AUTOSAR XML (schema 4-3-0)
standard types defined: boolean, float32, boolean_CompuMethod, boolean_DataConstr, float32_DataConstr, sint16, sint32, uint32, uint8, sint16_DataConstr, sint32_DataConstr, uint32_DataConstr, uint8_DataConstr, uint16
package /ASP_DataTypes
  impl type As_Coord2F32: category=STRUCTURE
    element x: implementation-data-type=ASP_DataTypes/float32
    element y: implementation-data-type=ASP_DataTypes/float32
package /ComponentTypes/HkmcComponent/HkmcFcaAdap
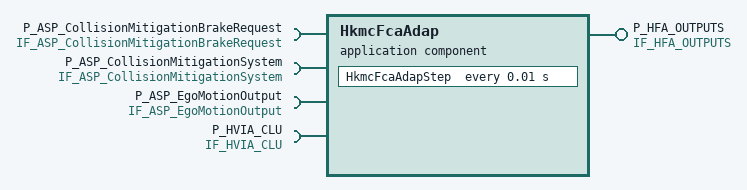
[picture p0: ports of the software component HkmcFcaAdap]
  application sw component type HkmcFcaAdap
    provide port P_HFA_OUTPUTS: nonqueued-sender-com-spec{data-element=DE_HFA_OUTPUTS, init-value=fields=[FcaAdap_WrngLvlSta:0, FcaAdap_WrngSndSta:0, FcaAdap_PrefillActvReq:0, FcaAdap_DclReqVal:0, FcaAdap_FullActvReq:0, FcaAdap_StbltActvReq:0, FcaAdap_VehStpReq:0, FcaAdap_OnOffEquipSta:0, FcaAdap_SysFlrSta:0, FcaAdap_RelVel:0, FcaAdap_TimetoCllsn:0, FcaAdap_SnstvtyModRetVal:0, FcaAdap_LongitudinalVelocity:0, FcaAdap_ObjectType:0, FcaAdap_WarningRequest:0, FcaAdap_CollisionThreatLevel:0, FcaAdap_DecelerationRequest:0, FcaAdap_StandStillRequest:0]}, provided-interface=IF_HFA_OUTPUTS
    4 x require port:
      P_ASP_CollisionMitigationBrakeRequest: nonqueued-receiver-com-spec{data-element=DE_ASP_CollisionMitigationBrakeRequest, filter=data-filter-type=ALWAYS, init-value=fields=[DecelerationEnabled:0, DecelerationRequest:0, StandStillRequest:0]}, required-interface=IF_ASP_CollisionMitigationBrakeRequest
      P_ASP_CollisionMitigationSystem: nonqueued-receiver-com-spec{data-element=DE_ASP_CollisionMitigationSystem, filter=data-filter-type=ALWAYS, init-value=fields=[{short-label=ForwardWarningControl, fields=[WarningRequest:0, ObjectType:0, BrakeGainEnabled:0, BrakeGainRequest:0, BrakeGainMaxDeceleration:0, TimeToCollision:0, ObjectId:0, {short-label=ObjectPosition, fields=[x:0, y:0]}]}, {short-label=ThreatInformation, fields=[BeltActivationLevel:0, CollisionThreatLevel:0, DisplayPostEventMessage:0]}]}, required-interface=IF_ASP_CollisionMitigationSystem
      P_ASP_EgoMotionOutput: nonqueued-receiver-com-spec{data-element=DE_ASP_EgoMotionOutput, filter=data-filter-type=ALWAYS, init-value=fields=[LongitudinalVelocity:0, LongitudinalAcceleration:0, LateralVelocity:0, LateralAcceleration:0, YawRate:0, IsAvailable:0, Timestamp:0, LongitudinalVelocityStatus:0, AccelerationStatus:0, YawRateStatus:0]}, required-interface=IF_ASP_EgoMotionOutput
      P_HVIA_CLU: nonqueued-receiver-com-spec{data-element=DE_HVIA_CLU, filter=data-filter-type=ALWAYS, init-value=fields=[HkmcVehicleInput_SpdUnitTyp:0, HkmcVehicleInput_Fca1stWrngSetReq:0, HkmcVehicleInput_AdasFCASetReq:0, HkmcVehicleInput_LkaModSetReq:0, HkmcVehInput_HBA_NValueSet:0]}, required-interface=IF_HVIA_CLU
    behavior HkmcFcaAdap_InternalBehavior
      timing event HkmcFcaAdap_TE: start-on-event=HkmcFcaAdapStep, period=0.01
      runnable HkmcFcaAdapStep
        data-receive-point-by-arguments:
          4 x access:
            REC_P_ASP_CollisionMitigationBrakeRequest_DE_ASP_CollisionMitigationBrakeRequest: accessed-variable=P_ASP_CollisionMitigationBrakeRequest.DE_ASP_CollisionMitigationBrakeRequest
            REC_P_ASP_CollisionMitigationSystem_DE_ASP_CollisionMitigationSystem: accessed-variable=P_ASP_CollisionMitigationSystem.DE_ASP_CollisionMitigationSystem
            REC_P_ASP_EgoMotionOutput_DE_ASP_EgoMotionOutput: accessed-variable=P_ASP_EgoMotionOutput.DE_ASP_EgoMotionOutput
            REC_P_HVIA_CLU_DE_HVIA_CLU: accessed-variable=P_HVIA_CLU.DE_HVIA_CLU
        data-send-points:
          access SEND_P_HFA_OUTPUTS_DE_HFA_OUTPUTS: accessed-variable=P_HFA_OUTPUTS.DE_HFA_OUTPUTS
  swc implementation HkmcFcaAdap_Implementation: behavior=HkmcFcaAdap_InternalBehavior
    code-descriptors:
      code Default: artifact-descriptors=autosar-engineering-object={short-label=Default, category=SWSRC}
package /ComponentTypes/HkmcComponent/HkmcFcaAdap/DataTypes
  27 x impl type:
    ASP_CollisionMitigationBrakeRequest_T: category=STRUCTURE
      element DecelerationEnabled: implementation-data-type=ASP_DataTypes/boolean  # Enable deceleration request
      element DecelerationRequest: implementation-data-type=ASP_DataTypes/float32  # Deceleration requested
      element StandStillRequest: implementation-data-type=ASP_DataTypes/boolean  # Request to hold the vehicle stationary until driver presses the acceleration pedal
    ASP_CollisionMitigationSystem_T: category=STRUCTURE
      element ForwardWarningControl: implementation-data-type=ForwardWarningControl  # Examples of driver alerts are audio, visual and haptic (brake pulse) warning
      element ThreatInformation: implementation-data-type=ThreatInformation
    ASP_EgoMotionOutput_T: category=STRUCTURE, sw-calibration-access=READ-ONLY, type-emitter=RTE
      10 x element, all with category=TYPE_REFERENCE:
        LongitudinalVelocity: implementation-data-type=sint16
        LongitudinalAcceleration: implementation-data-type=sint16
        LateralVelocity: implementation-data-type=sint16
        LateralAcceleration: implementation-data-type=sint16
        YawRate: implementation-data-type=sint16
        IsAvailable: implementation-data-type=ImplementationDataTypes/boolean
        Timestamp: implementation-data-type=uint32
        LongitudinalVelocityStatus: compu {0=Cx0_LongVS_Unknown, 1=Cx1_LongVS_SuccessfulVerification, 2=Cx2_LongVS_VerificationFailed}, implementation-data-type=uint8
        AccelerationStatus: compu {0=Cx0_AccelerationS_Unknown, 1=Cx1_AccelerationS_SuccessfulVerification, 2=Cx2_AccelerationS_VerificationFailed}, implementation-data-type=uint8
        YawRateStatus: compu {0=Cx0_YawRateS_Unknown, 1=Cx1_YawRateS_SuccessfulVerification, 2=Cx2_YawRateS_VerificationFailed}, implementation-data-type=uint8
    BeltActivationLevel_T: category=VALUE, base-type=BaseTypes/uint8, sw-calibration-access=READ-ONLY, compu {0=Cx0_NoActivation, 1=Cx1_ActivationLow, 2=Cx2_ActivationHigh, 3=Cx3_NotInUse}, type-emitter=RTE
    CollisionThreatLevel_T: category=VALUE, base-type=BaseTypes/uint8, sw-calibration-access=READ-ONLY, compu {0=Cx0_ASPCollisionTL_Unknown, 1=Cx1_ASPCollisionTL_ThreatLow, 2=Cx2_ASPCollisionTL_ThreatMedium, 3=Cx3_ASPCollisionTL_ThreatHigh}, type-emitter=RTE
    DisplayPostEventMessage_T: category=VALUE, base-type=BaseTypes/uint8, sw-calibration-access=READ-ONLY, compu {0=Cx0_NoMessage, 1=Cx1_InterventionLongitudinal, 2=Cx2_InterventionLateral, 3=Cx3_InterventionLongitudinalAndInterventionLateral, 4=Cx4_BrakePulse, 5=Cx5_CriteriaBrakeMessage}, type-emitter=RTE
    FcaAdap_CollisionThreatLevel_T: category=VALUE, base-type=BaseTypes/uint8, sw-calibration-access=READ-ONLY, compu {0=Cx0_CollisionTL_Unknown, 1=Cx1_CollisionTL_ThreatLow, 2=Cx2_CollisionTL_ThreatMedium, 3=Cx3_CollisionTL_ThreatHigh}, type-emitter=RTE
    FcaAdap_DclReqVal_T: category=VALUE, base-type=BaseTypes/uint8, sw-calibration-access=READ-ONLY, type-emitter=RTE
    FcaAdap_DecelerationRequest_T: category=VALUE, base-type=BaseTypes/uint8, sw-calibration-access=READ-ONLY, type-emitter=RTE
    FcaAdap_FullActvReq_T: category=VALUE, base-type=BaseTypes/uint8, sw-calibration-access=READ-ONLY, type-emitter=RTE
    FcaAdap_LongitudinalVelocity_T: category=VALUE, base-type=BaseTypes/sint16, sw-calibration-access=READ-ONLY, type-emitter=RTE
    FcaAdap_ObjectType_T: category=VALUE, base-type=BaseTypes/uint8, sw-calibration-access=READ-ONLY, compu {0=Cx0_ObT_Unknown, 1=Cx1_ObT_Car, 2=Cx2_ObT_Motorcycle, 3=Cx3_ObT_Truck, 4=Cx4_ObT_Pedestrian, 5=Cx5_ObT_Bicycle, 6=Cx6_ObT_GeneralObject}, type-emitter=RTE
    FcaAdap_OnOffEquipSta_T: category=VALUE, base-type=BaseTypes/uint8, sw-calibration-access=READ-ONLY, compu {0=Cx0_OnOffES_Default, 1=Cx1_OnOffES_Off, 2=Cx2_OnOffES_Warning, 3=Cx3_OnOffES_Assist, 4=Cx4_OnOffES_Reserved, 5=Cx5_OnOffES_Reserved, 6=Cx6_OnOffES_Reserved, 7=Cx7_OnOffES_Invalid}, type-emitter=RTE
    FcaAdap_PrefillActvReq_T: category=VALUE, base-type=BaseTypes/uint8, sw-calibration-access=READ-ONLY, compu {0=Cx0_PrefillAR_No_Pre_fill, 1=Cx1_PrefillAR_Pre_fill_act, 2=Cx2_PrefillAR_Reserved, 3=Cx3_PrefillAR_Error_Indicator}, type-emitter=RTE
    FcaAdap_RelVel_T: category=VALUE, base-type=uint16, sw-calibration-access=READ-ONLY, type-emitter=RTE
    FcaAdap_SnstvtyModRetVal_T: category=VALUE, base-type=BaseTypes/uint8, sw-calibration-access=READ-ONLY, compu {0=Cx0_LongV_Default, 1=Cx1_LongV_Off, 2=Cx2_LongV_Warning, 3=Cx3_LongV_Assist, 4=Cx4_LongV_Reserved, 5=Cx5_LongV_Reserved, 6=Cx6_LongV_Reserved, 7=Cx7_LongV_Invalid}, type-emitter=RTE
    FcaAdap_StbltActvReq_T: category=VALUE, base-type=BaseTypes/uint8, sw-calibration-access=READ-ONLY, compu {0=Cx0_StbltAR_Release_no_alert, 1=Cx1_StbltAR_Precrash_full_retraction, 2=Cx2_StbltAR_Haptic_Warning, 3=Cx3_StbltAR_Reserved, 4=Cx4_StbltAR_Reserved, 5=Cx5_StbltAR_Reserved, 6=Cx6_StbltAR_Reserved, 7=Cx7_StbltAR_Reserved}, type-emitter=RTE
    FcaAdap_SysFlrSta_T: category=VALUE, base-type=BaseTypes/uint8, sw-calibration-access=READ-ONLY, compu {0=Cx0_SysFlrS_Normal, 1=Cx1_SysFlrS_Temp_Unavailable_by_Camera, 2=Cx2_SysFlrS_Temp_Unavailable_by_Radar, 3=Cx3_SysFlrS_Service_Required, 4=Cx4_SysFlrS_Temp_Unavailable_by_Camera, 5=Cx5_SysFlrS_Reserved, 6=Cx6_SysFlrS_Reserved, 7=Cx7_SysFlrS_Reserved}, type-emitter=RTE
    FcaAdap_TimetoCllsn_T: category=VALUE, base-type=BaseTypes/uint8, sw-calibration-access=READ-ONLY, type-emitter=RTE
    FcaAdap_VehStpReq_T: category=VALUE, base-type=BaseTypes/uint8, sw-calibration-access=READ-ONLY, compu {0=Cx0_VehSR_No_Request, 1=Cx1_VehSR_Stop_control_is_required, 2=Cx2_VehSR_Reserved, 3=Cx3_VehSR_Error_Indicator}, type-emitter=RTE
    FcaAdap_WarningRequest_T: category=VALUE, base-type=BaseTypes/boolean, sw-calibration-access=READ-ONLY, type-emitter=RTE
    FcaAdap_WrngLvlSta_T: category=VALUE, base-type=BaseTypes/uint8, sw-calibration-access=READ-ONLY, compu {0=Cx0_WrngLS_No_warning, 1=Cx1_WrngLS_Warning_Level_1, 2=Cx2_WrngLS_Warning_Level_2, 3=Cx3_WrngLS_Warning_Level_3}, type-emitter=RTE
    FcaAdap_WrngSndSta_T: category=VALUE, base-type=BaseTypes/uint8, sw-calibration-access=READ-ONLY, compu {0=Cx0_WrngSS_No_warning, 1=Cx1_WrngSS_Warning_Level_1, 2=Cx2_WrngSS_Warning_Level_2, 3=Cx3_WrngSS_Warning_Level_3}, type-emitter=RTE
    ForwardWarningControl: category=STRUCTURE
      8 x element, all with category=TYPE_REFERENCE:
        WarningRequest: implementation-data-type=ImplementationDataTypes/boolean  # Request to activate collision warning against forward object
        ObjectType: implementation-data-type=ForwardWarningControl_ObjectType  # The object type that is source of the request to activate collision warning against forward object
        BrakeGainEnabled: implementation-data-type=ImplementationDataTypes/boolean  # Request to indicate that the current brake pressure should be amplified
        BrakeGainRequest: implementation-data-type=ImplementationDataTypes/float32  # Factor to increase brake pressure by
        BrakeGainMaxDeceleration: implementation-data-type=ImplementationDataTypes/float32  # Brake gain amplification should not cause the deceleration to be more negative than this value
        TimeToCollision: implementation-data-type=ImplementationDataTypes/float32  # Time to collision for primary target. Set to 100s if no value is available.
        ObjectId: implementation-data-type=uint8  # Id of selected object for collision warning. Note that a value of 0 indicates 'no object'.
        ObjectPosition: implementation-data-type=As_Coord2F32  # Position of selected object for collision warning, expressed in ARAC.
    ForwardWarningControl_ObjectType: compu {0=Cx0_ASPObT_Unknown, 1=Cx1_ASPObT_Car, 2=Cx2_ASPObT_Motorcycle, 3=Cx3_ASPObT_Truck, 4=Cx4_ASPObT_Pedestrian, 5=Cx5_ASPObT_Bicycle, 6=Cx6_ASPObT_GeneralObject}, implementation-data-type=sint32
    HFA_OUTPUTS_T: category=STRUCTURE, sw-calibration-access=READ-ONLY, type-emitter=RTE
      18 x element, all with category=TYPE_REFERENCE:
        FcaAdap_WrngLvlSta: implementation-data-type=FcaAdap_WrngLvlSta_T
        FcaAdap_WrngSndSta: implementation-data-type=FcaAdap_WrngSndSta_T
        FcaAdap_PrefillActvReq: implementation-data-type=FcaAdap_PrefillActvReq_T
        FcaAdap_DclReqVal: implementation-data-type=FcaAdap_DclReqVal_T
        FcaAdap_FullActvReq: implementation-data-type=FcaAdap_FullActvReq_T
        FcaAdap_StbltActvReq: implementation-data-type=FcaAdap_StbltActvReq_T
        FcaAdap_VehStpReq: implementation-data-type=FcaAdap_VehStpReq_T
        FcaAdap_OnOffEquipSta: implementation-data-type=FcaAdap_OnOffEquipSta_T
        FcaAdap_SysFlrSta: implementation-data-type=FcaAdap_SysFlrSta_T
        FcaAdap_RelVel: implementation-data-type=FcaAdap_RelVel_T
        FcaAdap_TimetoCllsn: implementation-data-type=FcaAdap_TimetoCllsn_T
        FcaAdap_SnstvtyModRetVal: implementation-data-type=FcaAdap_SnstvtyModRetVal_T
        FcaAdap_LongitudinalVelocity: implementation-data-type=FcaAdap_LongitudinalVelocity_T
        FcaAdap_ObjectType: implementation-data-type=FcaAdap_ObjectType_T
        FcaAdap_WarningRequest: implementation-data-type=FcaAdap_WarningRequest_T
        FcaAdap_CollisionThreatLevel: implementation-data-type=FcaAdap_CollisionThreatLevel_T
        FcaAdap_DecelerationRequest: implementation-data-type=FcaAdap_DecelerationRequest_T
        FcaAdap_StandStillRequest: implementation-data-type=ImplementationDataTypes/boolean
    ThreatInformation: category=STRUCTURE
      element BeltActivationLevel: implementation-data-type=BeltActivationLevel_T  # A request to activate the electric belts
      element CollisionThreatLevel: implementation-data-type=CollisionThreatLevel_T  # The current collision threat level. Used by vehicle mode management to reduce electrical loads in the car and thus increase system voltage.
      element DisplayPostEventMessage: implementation-data-type=DisplayPostEventMessage_T  # Request to driver information system to display post event message
package /ComponentTypes/HkmcComponent/HkmcFcaAdap/PortInterfaces
  5 x sender receiver interface:
    IF_ASP_CollisionMitigationBrakeRequest: invalidation-policy{data-element=DE_ASP_CollisionMitigationBrakeRequest, handle-invalid=DONT-INVALIDATE}
      data DE_ASP_CollisionMitigationBrakeRequest: type=ASP_CollisionMitigationBrakeRequest_T
    IF_ASP_CollisionMitigationSystem: invalidation-policy{data-element=DE_ASP_CollisionMitigationSystem, handle-invalid=DONT-INVALIDATE}
      data DE_ASP_CollisionMitigationSystem: type=ASP_CollisionMitigationSystem_T
    IF_ASP_EgoMotionOutput: invalidation-policy{data-element=DE_ASP_EgoMotionOutput, handle-invalid=DONT-INVALIDATE}
      data DE_ASP_EgoMotionOutput: type=ASP_EgoMotionOutput_T
    IF_HFA_OUTPUTS: invalidation-policy{data-element=DE_HFA_OUTPUTS, handle-invalid=DONT-INVALIDATE}
      data DE_HFA_OUTPUTS: type=HFA_OUTPUTS_T
    IF_HVIA_CLU: invalidation-policy{data-element=DE_HVIA_CLU, handle-invalid=DONT-INVALIDATE}
      data DE_HVIA_CLU: type=HVIA_CLU_T
package /ComponentTypes/HkmcComponent/HkmcVehicleInputAdap/DataTypes
  impl type HVIA_CLU_T: category=STRUCTURE, sw-calibration-access=READ-ONLY, type-emitter=RTE
    5 x element, all with category=TYPE_REFERENCE, implementation-data-type=uint8:
      HkmcVehicleInput_SpdUnitTyp: compu {0=Cx0_SpdUT_kmperh, 1=Cx1_SpdUT_MPH, 2=Cx2_SpdUT_Not_used, 3=Cx3_SpdUT_Error_Indicator}
      HkmcVehicleInput_Fca1stWrngSetReq: compu {0=Cx0_Fca1stWSR_Default, 1=Cx1_Fca1stWSR_LDW_Mode, 2=Cx2_Fca1stWSR_LKA_Mode, 3=Cx3_Fca1stWSR_Reserved, 4=Cx4_Fca1stWSR_Reserved, 5=Cx5_Fca1stWSR_Reserved, 6=Cx6_Fca1stWSR_Reserved, 7=Cx7_Fca1stWSR_Invalid}
      HkmcVehicleInput_AdasFCASetReq: compu {0=Cx0_AdasFCASR_Default, 1=Cx1_AdasFCASR_Off, 2=Cx2_AdasFCASR_Warning, 3=Cx3_AdasFCASR_Assist, 4=Cx4_AdasFCASR_Reserved, 5=Cx5_AdasFCASR_Reserved, 6=Cx6_AdasFCASR_Reserved, 7=Cx7_AdasFCASR_Invalid}
      HkmcVehicleInput_LkaModSetReq: compu {0=Cx0_LkaModSR_Default, 1=Cx1_LkaModSR_LDW_mode, 2=Cx2_LkaModSR_LKA_mode, 3=Cx3_LkaModSR_ACTIVE_LKA, 4=Cx4_LkaModSR_LDW_ON, 5=Cx5_LkaModSR_LDW_OFF, 6=Cx6_LkaModSR_LDW_LKA_OFF, 7=Cx7_LkaModSR_Invalid}
      HkmcVehInput_HBA_NValueSet: compu {0=Cx0_NVS_Default, 1=Cx1_NVS_HBA_Off, 2=Cx2_NVS_HBA_On, 3=Cx3_NVS_Invalid}
